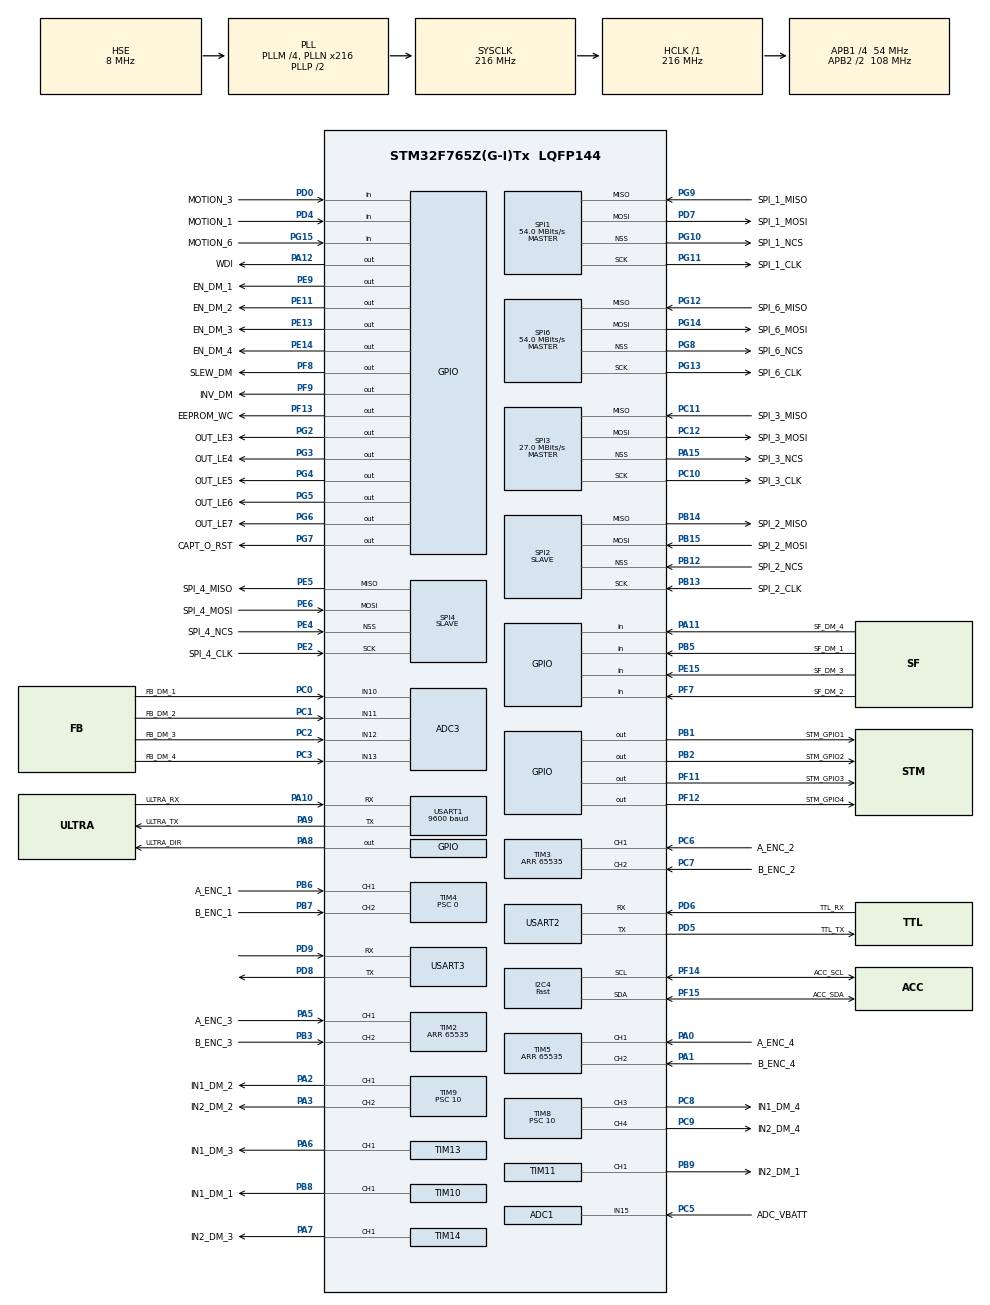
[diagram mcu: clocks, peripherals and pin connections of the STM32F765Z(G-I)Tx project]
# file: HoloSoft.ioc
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SPI6.Mode=SPI_MODE_MASTER
PD7.Mode=Full_Duplex_Master
SPI3.Direction=SPI_DIRECTION_2LINES
SPI4.VirtualType=VM_SLAVE
SPI3.VirtualType=VM_MASTER
SPI1.VirtualType=VM_MASTER
SPI2.VirtualType=VM_SLAVE
VP_ADC1_TempSens_Input.Mode=IN-TempSens
NVIC.TIM6_DAC_IRQn=true\:1\:0\:true\:false\:true\:true\:true
PG4.Signal=GPIO_Output
PG8.Signal=SPI6_NSS
PC12.Signal=SPI3_MOSI
PB14.GPIO_Label=SPI_2_MISO
PG6.GPIO_Label=OUT_LE7
PA14.GPIO_Label=STM_SWCLK
PC6.GPIO_Label=A_ENC_2
PA6.GPIO_Label=IN1_DM_3
PB6.GPIO_Label=A_ENC_1
TIM8.Channel-PWM\ Generation4\ CH4=TIM_CHANNEL_4
PB13.Signal=SPI2_SCK
PD6.GPIO_Label=TTL_RX
PG13.Signal=SPI6_SCK
PE6.GPIO_Label=SPI_4_MOSI
RCC.SYSCLKSource=RCC_SYSCLKSOURCE_PLLCLK
USART3.VirtualMode-Asynchronous=VM_ASYNC
NVIC.SPI4_IRQn=true\:7\:0\:true\:false\:true\:true\:true
PG15.GPIO_Label=MOTION_6
PF7.Signal=GPIO_Input
SH.S_TIM14_CH1.0=TIM14_CH1,PWM Generation1 CH1
I2C4.Timing=0x6000030D
SPI1.Direction=SPI_DIRECTION_2LINES
SPI3.VirtualNSS=VM_NSSHARD
PE2.Mode=Full_Duplex_Slave
PD4.Signal=GPIO_Input
RCC.APB2TimFreq_Value=216000000
PB6.Signal=S_TIM4_CH1
VP_TIM10_VS_ClockSourceINT.Mode=Enable_Timer
PC7.Signal=S_TIM3_CH2
PH1/OSC_OUT.Signal=RCC_OSC_OUT
SPI1.CalculateBaudRate=54.0 MBits/s
PC3.Signal=ADCx_IN13
PD0.Signal=GPIO_Input
PD8.Signal=USART3_TX
PE5.Signal=SPI4_MISO
PB2.Signal=GPIO_Output
ADC3.SamplingTime-2\#ChannelRegularConversion=ADC_SAMPLETIME_3CYCLES
TIM10.Channel=TIM_CHANNEL_1
SH.ADCx_IN15.0=ADC1_IN15,IN15
PB12.GPIO_Label=SPI_2_NCS
PG14.Mode=Full_Duplex_Master
PF12.GPIO_Label=STM_GPIO4
PE9.Signal=GPIO_Output
PB14.Mode=Full_Duplex_Slave
PB1.GPIO_Label=STM_GPIO1
SPI1.DataSize=SPI_DATASIZE_8BIT
PG4.GPIO_Label=OUT_LE5
PE4.GPIO_Label=SPI_4_NCS
SH.S_TIM4_CH2.0=TIM4_CH2,Encoder_Interface
PE2.Signal=SPI4_SCK
PA8.Signal=GPIO_Output
SPI1.VirtualNSS=VM_NSSHARD
TIM4.Period=65535
ADC3.Channel-2\#ChannelRegularConversion=ADC_CHANNEL_12
ADC1.SamplingTime-0\#ChannelRegularConversion=ADC_SAMPLETIME_3CYCLES
TIM9.Prescaler=10
Mcu.Package=LQFP144
PB9.Signal=S_TIM11_CH1
PB1.Signal=GPIO_Output
PB14.GPIO_PuPd=GPIO_PULLUP
TIM8.Channel-PWM\ Generation3\ CH3=TIM_CHANNEL_3
SH.S_TIM8_CH4.0=TIM8_CH4,PWM Generation4 CH4
SPI2.Mode=SPI_MODE_SLAVE
SPI3.Mode=SPI_MODE_MASTER
ADC3.Rank-0\#ChannelRegularConversion=1
PA10.Signal=USART1_RX
PC11.Mode=Full_Duplex_Master
RCC.APB2CLKDivider=RCC_HCLK_DIV2
SH.S_TIM4_CH1.0=TIM4_CH1,Encoder_Interface
PF14.Signal=I2C4_SCL
RCC.APB1TimFreq_Value=108000000
PB13.Mode=Full_Duplex_Slave
VP_TIM14_VS_ClockSourceINT.Mode=Enable_Timer
NVIC.USART1_IRQn=true\:7\:0\:true\:false\:true\:true\:true
TIM9.Period=999
PG12.Signal=SPI6_MISO
TIM9.Channel-PWM\ Generation2\ CH2=TIM_CHANNEL_2
SH.S_TIM8_CH3.0=TIM8_CH3,PWM Generation3 CH3
TIM9.Channel-PWM\ Generation1\ CH1=TIM_CHANNEL_1
I2C4.I2C_Speed_Mode=I2C_Fast
ADC1.Rank-0\#ChannelRegularConversion=1
PG5.Signal=GPIO_Output
PG9.Signal=SPI1_MISO
PA9.GPIO_Label=ULTRA_TX
PG9.Mode=Full_Duplex_Master
PC6.Signal=S_TIM3_CH1
PC2.Signal=ADCx_IN12
PD7.Signal=SPI1_MOSI
PA11.GPIO_Label=SF_DM_4
PF14.GPIO_Label=ACC_SCL
SPI1.CLKPhase=SPI_PHASE_2EDGE
TIM11.Prescaler=10
PC0.Signal=ADCx_IN10
RCC.APB1CLKDivider=RCC_HCLK_DIV4
PD6.Mode=Asynchronous
PF13.GPIO_Label=EEPROM_WC
PG13.GPIO_Label=SPI_6_CLK
PG10.Signal=SPI1_NSS
PF8.GPIO_Label=SLEW_DM
PB8.GPIO_Label=IN1_DM_1
PA8.GPIO_Label=ULTRA_DIR
SPI6.CalculateBaudRate=54.0 MBits/s
TIM13.Channel=TIM_CHANNEL_1
SH.S_TIM9_CH2.0=TIM9_CH2,PWM Generation2 CH2
PA9.Signal=USART1_TX
VP_TIM8_VS_ClockSourceINT.Mode=Internal
SPI4.VirtualNSS=VM_NSSHARD
ADC3.NbrOfConversion=4
PE9.GPIO_Label=EN_DM_1
PD8.Mode=Asynchronous
PB14.Signal=SPI2_MISO
PE2.GPIO_PuPd=GPIO_NOPULL
PA5.Signal=S_TIM2_CH1_ETR
PC12.Mode=Full_Duplex_Master
TIM13.Period=999
PB13.GPIO_PuPd=GPIO_PULLUP
NVIC.SPI1_IRQn=true\:7\:0\:true\:false\:true\:true\:true
VP_TIM13_VS_ClockSourceINT.Mode=Enable_Timer
PE14.Signal=GPIO_Output
PE6.Mode=Full_Duplex_Slave
PE15.Signal=GPIO_Input
TIM14.Channel=TIM_CHANNEL_1
PB15.GPIO_Label=SPI_2_MOSI
TIM13.Prescaler=5
SPI1.Mode=SPI_MODE_MASTER
PG7.GPIO_Label=CAPT_O_RST
PA1.GPIO_Label=B_ENC_4
SH.S_TIM9_CH1.0=TIM9_CH1,PWM Generation1 CH1
PA0/WKUP.GPIO_Label=A_ENC_4
PF13.Signal=GPIO_Output
TIM2.Period=65535
PA13.Mode=Serial_Wire
PG14.GPIO_Label=SPI_6_MOSI
ADC3.Channel-1\#ChannelRegularConversion=ADC_CHANNEL_11
TIM14.Prescaler=5
PE4.GPIO_PuPd=GPIO_NOPULL
TIM8.Period=999
PC7.GPIO_Label=B_ENC_2
ADC3.Rank-1\#ChannelRegularConversion=2
ADC1.SamplingTime-1\#ChannelRegularConversion=ADC_SAMPLETIME_3CYCLES
PB5.Signal=GPIO_Input
ADC1.master=1
PE13.GPIO_Label=EN_DM_3
PA5.GPIO_Label=A_ENC_3
PE5.GPIO_Label=SPI_4_MISO
PC12.GPIO_Label=SPI_3_MOSI
ADC1.Rank-1\#ChannelRegularConversion=2
PG11.Mode=Full_Duplex_Master
PA11.Signal=GPIO_Input
SH.S_TIM2_CH1_ETR.0=TIM2_CH1,Encoder_Interface
ProjectManager.HeapSize=0x200
PF9.Signal=GPIO_Output
SPI4.CLKPhase=SPI_PHASE_2EDGE
NVIC.PriorityGroup=NVIC_PRIORITYGROUP_4
PC3.GPIO_Label=FB_DM_4
SPI2.DataSize=SPI_DATASIZE_8BIT
PG3.GPIO_Label=OUT_LE4
PC1.Signal=ADCx_IN11
PG10.GPIO_Label=SPI_1_NCS
SPI6.VirtualType=VM_MASTER
Mcu.Family=STM32F7
NVIC.USART3_IRQn=true\:0\:0\:false\:false\:true\:true\:true
PG8.Mode=NSS_Signal_Hard_Output
NVIC.SPI6_IRQn=true\:7\:0\:true\:false\:true\:true\:true
SPI2.VirtualNSS=VM_NSSHARD
RCC.CortexFreq_Value=216000000
PG6.Signal=GPIO_Output
ADC3.Channel-3\#ChannelRegularConversion=ADC_CHANNEL_13
PG2.Signal=GPIO_Output
PE11.GPIO_Label=EN_DM_2
USART1.BaudRate=9600
PC10.Signal=SPI3_SCK
TIM4.EncoderMode=TIM_ENCODERMODE_TI12
TIM5.EncoderMode=TIM_ENCODERMODE_TI12
SPI4.Direction=SPI_DIRECTION_2LINES
TIM3.EncoderMode=TIM_ENCODERMODE_TI12
SH.S_TIM5_CH2.0=TIM5_CH2,Encoder_Interface
PC0.GPIO_Label=FB_DM_1
PD0.GPIO_Label=MOTION_3
PA0/WKUP.Signal=S_TIM5_CH1
TIM2.EncoderMode=TIM_ENCODERMODE_TI12
PB13.GPIO_Label=SPI_2_CLK
PG5.GPIO_Label=OUT_LE6
PB15.Signal=SPI2_MOSI
ADC3.Channel-0\#ChannelRegularConversion=ADC_CHANNEL_10
PD9.Mode=Asynchronous
SH.S_TIM13_CH1.0=TIM13_CH1,PWM Generation1 CH1
PG11.Signal=SPI1_SCK
PG15.Signal=GPIO_Input
ADC3.Rank-2\#ChannelRegularConversion=3
ProjectManager.StackSize=0x400
VP_TIM7_VS_ClockSourceINT.Mode=Enable_Timer
NVIC.ADC_IRQn=true\:4\:0\:true\:false\:true\:true\:true
PA15.GPIO_Label=SPI_3_NCS
PA12.Signal=GPIO_Output
SPI1.CLKPolarity=SPI_POLARITY_HIGH
SPI2.CLKPolarity=SPI_POLARITY_HIGH
SPI4.Mode=SPI_MODE_SLAVE
SPI3.CLKPolarity=SPI_POLARITY_HIGH
PH0/OSC_IN.Mode=HSE-External-Oscillator
RCC.HCLKFreq_Value=216000000
TIM3.Period=65535
PF11.GPIO_Label=STM_GPIO3
PF12.Signal=GPIO_Output
SPI6.CLKPolarity=SPI_POLARITY_HIGH
TIM7.Period=199
SPI4.CLKPolarity=SPI_POLARITY_HIGH
RCC.AHBFreq_Value=216000000
SPI3.DataSize=SPI_DATASIZE_8BIT
PD5.Mode=Asynchronous
ADC3.SamplingTime-1\#ChannelRegularConversion=ADC_SAMPLETIME_3CYCLES
ADC1.Channel-0\#ChannelRegularConversion=ADC_CHANNEL_15
RCC.HSE_VALUE=8000000
USART2.VirtualMode-Asynchronous=VM_ASYNC
TIM14.Period=999
PA15.Mode=NSS_Signal_Hard_Output
PE13.Signal=GPIO_Output
PF7.GPIO_Label=SF_DM_2
PA14.Mode=Serial_Wire
PF11.Signal=GPIO_Output
PC11.GPIO_Label=SPI_3_MISO
PA10.GPIO_Label=ULTRA_RX
PB7.Signal=S_TIM4_CH2
NVIC.SPI2_IRQn=true\:7\:0\:true\:false\:true\:true\:true
PG13.Mode=Full_Duplex_Master
PE4.Mode=NSS_Signal_Hard_Input
SH.S_TIM3_CH1.0=TIM3_CH1,Encoder_Interface
TIM6.Period=9999
PH1/OSC_OUT.Mode=HSE-External-Oscillator
PE4.Signal=SPI4_NSS
PF15.Mode=I2C
PD7.GPIO_Label=SPI_1_MOSI
PB7.GPIO_Label=B_ENC_1
PA6.Signal=S_TIM13_CH1
PB12.Mode=NSS_Signal_Hard_Input
PB15.GPIO_PuPd=GPIO_PULLUP
SH.S_TIM10_CH1.0=TIM10_CH1,PWM Generation1 CH1
PD5.GPIO_Label=TTL_TX
PA2.GPIO_Label=IN1_DM_2
PA15.Signal=SPI3_NSS
PF8.Signal=GPIO_Output
NVIC.SPI3_IRQn=true\:7\:0\:true\:false\:true\:true\:true
SPI2.CLKPhase=SPI_PHASE_2EDGE
TIM8.Prescaler=10
PB5.GPIO_Label=SF_DM_1
SH.S_TIM5_CH1.0=TIM5_CH1,Encoder_Interface
PG11.GPIO_Label=SPI_1_CLK
SPI2.Direction=SPI_DIRECTION_2LINES
PC5.Signal=ADCx_IN15
PD6.Signal=USART2_RX
SH.S_TIM11_CH1.0=TIM11_CH1,PWM Generation1 CH1
PE2.GPIO_Label=SPI_4_CLK
PC2.GPIO_Label=FB_DM_3
NVIC.TIM7_IRQn=true\:1\:0\:true\:false\:true\:true\:true
PG2.GPIO_Label=OUT_LE3
PA3.Signal=S_TIM9_CH2
PB3.GPIO_Label=B_ENC_3
RCC.PLLSourceVirtual=RCC_PLLSOURCE_HSE
TIM10.Prescaler=10
SPI6.CLKPhase=SPI_PHASE_2EDGE
ADC3.SamplingTime-3\#ChannelRegularConversion=ADC_SAMPLETIME_3CYCLES
SH.ADCx_IN13.0=ADC3_IN13,IN13
PG7.Signal=GPIO_Output
PB9.GPIO_Label=IN2_DM_1
PA10.Mode=Asynchronous
PC10.GPIO_Label=SPI_3_CLK
PC9.GPIO_Label=IN2_DM_4
SPI4.DataSize=SPI_DATASIZE_8BIT
PG3.Signal=GPIO_Output
PC11.Signal=SPI3_MISO
PC8.Signal=S_TIM8_CH3
TIM6.Prescaler=10800
PC10.Mode=Full_Duplex_Master
PG10.Mode=NSS_Signal_Hard_Output
VP_TIM6_VS_ClockSourceINT.Mode=Enable_Timer
PE14.GPIO_Label=EN_DM_4
PD9.Signal=USART3_RX
PD5.Signal=USART2_TX
ADC3.Rank-3\#ChannelRegularConversion=4
NVIC.USART2_IRQn=true\:7\:0\:true\:false\:true\:true\:true
PA12.GPIO_Label=WDI
VP_TIM11_VS_ClockSourceINT.Mode=Enable_Timer
SPI6.VirtualNSS=VM_NSSHARD
PG8.GPIO_Label=SPI_6_NCS
PC8.GPIO_Label=IN1_DM_4
USART1.VirtualMode-Asynchronous=VM_ASYNC
PA13.Signal=SYS_JTMS-SWDIO
SH.S_TIM2_CH2.0=TIM2_CH2,Encoder_Interface
PA9.Mode=Asynchronous
SH.ADCx_IN12.0=ADC3_IN12,IN12
ADC3.SamplingTime-0\#ChannelRegularConversion=ADC_SAMPLETIME_3CYCLES
PE15.GPIO_Label=SF_DM_3
SPI6.DataSize=SPI_DATASIZE_8BIT
ProjectManager.TargetToolchain=STM32CubeIDE
ADC1.Channel-1\#ChannelRegularConversion=ADC_CHANNEL_TEMPSENSOR
RCC.USBFreq_Value=216000000
PF9.GPIO_Label=INV_DM
TIM4.Prescaler=0
PE11.Signal=GPIO_Output
RCC.LSE_VALUE=32768
PA1.Signal=S_TIM5_CH2
PG9.GPIO_Label=SPI_1_MISO
SH.S_TIM3_CH2.0=TIM3_CH2,Encoder_Interface
PG14.Signal=SPI6_MOSI
TIM7.Prescaler=10800
board=custom
PG12.Mode=Full_Duplex_Master
SPI3.CLKPhase=SPI_PHASE_2EDGE
RCC.VCOOutputFreq_Value=432000000
PB15.Mode=Full_Duplex_Slave
VP_TIM9_VS_ClockSourceINT.Mode=Internal
TIM11.Period=999
TIM10.Period=999
PH0/OSC_IN.Signal=RCC_OSC_IN
RCC.APB2Freq_Value=108000000
SPI3.CalculateBaudRate=27.0 MBits/s
SH.ADCx_IN11.0=ADC3_IN11,IN11
PD4.GPIO_Label=MOTION_1
PF14.Mode=I2C
PE5.Mode=Full_Duplex_Slave
PC1.GPIO_Label=FB_DM_2
PF15.GPIO_Label=ACC_SDA
SPI6.Direction=SPI_DIRECTION_2LINES
PF15.Signal=I2C4_SDA
PE6.Signal=SPI4_MOSI
ADC1.NbrOfConversion=2
Mcu.Name=STM32F765Z(G-I)Tx
PA2.Signal=S_TIM9_CH1
PA13.GPIO_Label=STM_SWSDIO
PB3.Signal=S_TIM2_CH2
RCC.SYSCLKFreq_VALUE=216000000
PA7.GPIO_Label=IN2_DM_3
PC5.GPIO_Label=ADC_VBATT
PA14.Signal=SYS_JTCK-SWCLK
SH.ADCx_IN10.0=ADC3_IN10,IN10
PB2.GPIO_Label=STM_GPIO2
PG12.GPIO_Label=SPI_6_MISO
RCC.HSI_VALUE=16000000
ADC1.NbrOfConversionFlag=1
RCC.PLLM=4
RCC.PLLN=216
TIM11.Channel=TIM_CHANNEL_1
PB8.Signal=S_TIM10_CH1
TIM5.Period=65535
PC9.Signal=S_TIM8_CH4
RCC.APB1Freq_Value=54000000
ADC3.NbrOfConversionFlag=1
PB12.Signal=SPI2_NSS
PA3.GPIO_Label=IN2_DM_2
PA7.Signal=S_TIM14_CH1

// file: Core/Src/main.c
/* USER CODE BEGIN Header */
/**
  ******************************************************************************
  * @file           : main.c
  * @brief          : Main program body
  ******************************************************************************
  * @attention
  *
  * <h2><center>&copy; Copyright (c) 2019 STMicroelectronics.
  * All rights reserved.</center></h2>
  *
  * This software component is licensed by ST under BSD 3-Clause license,
  * the "License"; You may not use this file except in compliance with the
  * License. You may obtain a copy of the License at:
  *                        opensource.org/licenses/BSD-3-Clause
  *
  ******************************************************************************
  */
/* USER CODE END Header */

#include "main.h"

/* USER CODE BEGIN Includes */
#include <stdio.h>
#include <string.h>
#include <math.h>
/* Includes ------------------------------------------------------------------*/
#include "main.h"
#include "secretary.h"
#include "brain.h"
#include "it.h"
#include "odometry.h"
/* Private includes ----------------------------------------------------------*/
/* USER CODE END Includes */

/* USER CODE BEGIN PD */
#define MATHS_PI				3.14159
//#define MATHS_PI_x2				6.28318
//#define CONVERT_RAD_TO_RPM	(60 / (MATHS_PI_x2))	// Coefficient de convertion RAD vers RPM

/* USER CODE END PD */

ADC_HandleTypeDef hadc1;
ADC_HandleTypeDef hadc3;

I2C_HandleTypeDef hi2c4;

SPI_HandleTypeDef hspi1;
SPI_HandleTypeDef hspi2;
SPI_HandleTypeDef hspi3;
SPI_HandleTypeDef hspi4;
SPI_HandleTypeDef hspi6;

TIM_HandleTypeDef htim2;
TIM_HandleTypeDef htim3;
TIM_HandleTypeDef htim4;
TIM_HandleTypeDef htim5;
TIM_HandleTypeDef htim6;
TIM_HandleTypeDef htim7;
TIM_HandleTypeDef htim8;
TIM_HandleTypeDef htim9;
TIM_HandleTypeDef htim10;
TIM_HandleTypeDef htim11;
TIM_HandleTypeDef htim13;
TIM_HandleTypeDef htim14;

UART_HandleTypeDef huart1;
UART_HandleTypeDef huart2;
UART_HandleTypeDef huart3;

void SystemClock_Config(void);
static void MX_GPIO_Init(void);
static void MX_SPI2_Init(void);
static void MX_USART1_UART_Init(void);
static void MX_I2C4_Init(void);
static void MX_SPI1_Init(void);
static void MX_SPI3_Init(void);
static void MX_SPI6_Init(void);
static void MX_USART2_UART_Init(void);
static void MX_USART3_UART_Init(void);
static void MX_SPI4_Init(void);
static void MX_ADC1_Init(void);
static void MX_ADC3_Init(void);
static void MX_TIM2_Init(void);
static void MX_TIM3_Init(void);
static void MX_TIM4_Init(void);
static void MX_TIM5_Init(void);
static void MX_TIM14_Init(void);
static void MX_TIM8_Init(void);
static void MX_TIM9_Init(void);
static void MX_TIM10_Init(void);
static void MX_TIM11_Init(void);
static void MX_TIM13_Init(void);
static void MX_TIM7_Init(void);
static void MX_TIM6_Init(void);
/* USER CODE BEGIN PFP */
static void board_message_init(void);
static void board_motors_init(void);
static void board_encodeurs_init(void);

/* USER CODE END PFP */

/* USER CODE BEGIN 0 */

uint16_t j=0;
uint8_t test_freq = 0;

/* USER CODE END 0 */

int main(void)
{

  /* MCU Configuration--------------------------------------------------------*/

  /* Reset of all peripherals, Initializes the Flash interface and the Systick. */
  HAL_Init();

  /* Configure the system clock */
  SystemClock_Config();

  /* Initialize all configured peripherals */
  MX_GPIO_Init();
  MX_SPI2_Init();
  MX_USART1_UART_Init();
  MX_I2C4_Init();
  MX_SPI1_Init();
  MX_SPI3_Init();
  MX_SPI6_Init();
  MX_USART2_UART_Init();
  MX_USART3_UART_Init();
  MX_SPI4_Init();
  MX_ADC1_Init();
  MX_ADC3_Init();
  MX_TIM2_Init();
  MX_TIM3_Init();
  MX_TIM4_Init();
  MX_TIM5_Init();
  MX_TIM14_Init();
  MX_TIM8_Init();
  MX_TIM9_Init();
  MX_TIM10_Init();
  MX_TIM11_Init();
  MX_TIM13_Init();
  MX_TIM7_Init();
  MX_TIM6_Init();
  /* USER CODE BEGIN 2 */

  board_message_init();
  board_motors_init();
  board_encodeurs_init();
  ODOMETRY_init();
  IT_init();
  BRAIN_main();
  /* USER CODE END 2 */

  /* Infinite loop */
  while (1)
  {

  }
}

void SystemClock_Config(void)
{
  RCC_OscInitTypeDef RCC_OscInitStruct = {0};
  RCC_ClkInitTypeDef RCC_ClkInitStruct = {0};
  RCC_PeriphCLKInitTypeDef PeriphClkInitStruct = {0};

  /** Configure the main internal regulator output voltage
  */
  __HAL_RCC_PWR_CLK_ENABLE();
  __HAL_PWR_VOLTAGESCALING_CONFIG(PWR_REGULATOR_VOLTAGE_SCALE1);
  /** Initializes the CPU, AHB and APB busses clocks
  */
  RCC_OscInitStruct.OscillatorType = RCC_OSCILLATORTYPE_HSE;
  RCC_OscInitStruct.HSEState = RCC_HSE_ON;
  RCC_OscInitStruct.PLL.PLLState = RCC_PLL_ON;
  RCC_OscInitStruct.PLL.PLLSource = RCC_PLLSOURCE_HSE;
  RCC_OscInitStruct.PLL.PLLM = 4;
  RCC_OscInitStruct.PLL.PLLN = 216;
  RCC_OscInitStruct.PLL.PLLP = RCC_PLLP_DIV2;
  RCC_OscInitStruct.PLL.PLLQ = 2;
  if (HAL_RCC_OscConfig(&RCC_OscInitStruct) != HAL_OK)
  {
    Error_Handler();
  }
  /** Activate the Over-Drive mode
  */
  if (HAL_PWREx_EnableOverDrive() != HAL_OK)
  {
    Error_Handler();
  }
  /** Initializes the CPU, AHB and APB busses clocks
  */
  RCC_ClkInitStruct.ClockType = RCC_CLOCKTYPE_HCLK|RCC_CLOCKTYPE_SYSCLK
                              |RCC_CLOCKTYPE_PCLK1|RCC_CLOCKTYPE_PCLK2;
  RCC_ClkInitStruct.SYSCLKSource = RCC_SYSCLKSOURCE_PLLCLK;
  RCC_ClkInitStruct.AHBCLKDivider = RCC_SYSCLK_DIV1;
  RCC_ClkInitStruct.APB1CLKDivider = RCC_HCLK_DIV4;
  RCC_ClkInitStruct.APB2CLKDivider = RCC_HCLK_DIV2;

  if (HAL_RCC_ClockConfig(&RCC_ClkInitStruct, FLASH_LATENCY_7) != HAL_OK)
  {
    Error_Handler();
  }
  PeriphClkInitStruct.PeriphClockSelection = RCC_PERIPHCLK_USART1|RCC_PERIPHCLK_USART2
                              |RCC_PERIPHCLK_USART3|RCC_PERIPHCLK_I2C4;
  PeriphClkInitStruct.Usart1ClockSelection = RCC_USART1CLKSOURCE_PCLK2;
  PeriphClkInitStruct.Usart2ClockSelection = RCC_USART2CLKSOURCE_PCLK1;
  PeriphClkInitStruct.Usart3ClockSelection = RCC_USART3CLKSOURCE_PCLK1;
  PeriphClkInitStruct.I2c4ClockSelection = RCC_I2C4CLKSOURCE_PCLK1;
  if (HAL_RCCEx_PeriphCLKConfig(&PeriphClkInitStruct) != HAL_OK)
  {
    Error_Handler();
  }
}

static void MX_ADC1_Init(void)
{

  ADC_ChannelConfTypeDef sConfig = {0};

  /** Configure the global features of the ADC (Clock, Resolution, Data Alignment and number of conversion)
  */
  hadc1.Instance = ADC1;
  hadc1.Init.ClockPrescaler = ADC_CLOCK_SYNC_PCLK_DIV4;
  hadc1.Init.Resolution = ADC_RESOLUTION_12B;
  hadc1.Init.ScanConvMode = ADC_SCAN_ENABLE;
  hadc1.Init.ContinuousConvMode = DISABLE;
  hadc1.Init.DiscontinuousConvMode = DISABLE;
  hadc1.Init.ExternalTrigConvEdge = ADC_EXTERNALTRIGCONVEDGE_NONE;
  hadc1.Init.ExternalTrigConv = ADC_SOFTWARE_START;
  hadc1.Init.DataAlign = ADC_DATAALIGN_RIGHT;
  hadc1.Init.NbrOfConversion = 2;
  hadc1.Init.DMAContinuousRequests = DISABLE;
  hadc1.Init.EOCSelection = ADC_EOC_SINGLE_CONV;
  if (HAL_ADC_Init(&hadc1) != HAL_OK)
  {
    Error_Handler();
  }
  /** Configure for the selected ADC regular channel its corresponding rank in the sequencer and its sample time.
  */
  sConfig.Channel = ADC_CHANNEL_15;
  sConfig.Rank = ADC_REGULAR_RANK_1;
  sConfig.SamplingTime = ADC_SAMPLETIME_3CYCLES;
  if (HAL_ADC_ConfigChannel(&hadc1, &sConfig) != HAL_OK)
  {
    Error_Handler();
  }
  /** Configure for the selected ADC regular channel its corresponding rank in the sequencer and its sample time.
  */
  sConfig.Channel = ADC_CHANNEL_TEMPSENSOR;
  sConfig.Rank = ADC_REGULAR_RANK_2;
  if (HAL_ADC_ConfigChannel(&hadc1, &sConfig) != HAL_OK)
  {
    Error_Handler();
  }

}

static void MX_ADC3_Init(void)
{

  ADC_ChannelConfTypeDef sConfig = {0};

  /** Configure the global features of the ADC (Clock, Resolution, Data Alignment and number of conversion)
  */
  hadc3.Instance = ADC3;
  hadc3.Init.ClockPrescaler = ADC_CLOCK_SYNC_PCLK_DIV4;
  hadc3.Init.Resolution = ADC_RESOLUTION_12B;
  hadc3.Init.ScanConvMode = ADC_SCAN_ENABLE;
  hadc3.Init.ContinuousConvMode = DISABLE;
  hadc3.Init.DiscontinuousConvMode = DISABLE;
  hadc3.Init.ExternalTrigConvEdge = ADC_EXTERNALTRIGCONVEDGE_NONE;
  hadc3.Init.ExternalTrigConv = ADC_SOFTWARE_START;
  hadc3.Init.DataAlign = ADC_DATAALIGN_RIGHT;
  hadc3.Init.NbrOfConversion = 4;
  hadc3.Init.DMAContinuousRequests = DISABLE;
  hadc3.Init.EOCSelection = ADC_EOC_SINGLE_CONV;
  if (HAL_ADC_Init(&hadc3) != HAL_OK)
  {
    Error_Handler();
  }
  /** Configure for the selected ADC regular channel its corresponding rank in the sequencer and its sample time.
  */
  sConfig.Channel = ADC_CHANNEL_10;
  sConfig.Rank = ADC_REGULAR_RANK_1;
  sConfig.SamplingTime = ADC_SAMPLETIME_3CYCLES;
  if (HAL_ADC_ConfigChannel(&hadc3, &sConfig) != HAL_OK)
  {
    Error_Handler();
  }
  /** Configure for the selected ADC regular channel its corresponding rank in the sequencer and its sample time.
  */
  sConfig.Channel = ADC_CHANNEL_11;
  sConfig.Rank = ADC_REGULAR_RANK_2;
  if (HAL_ADC_ConfigChannel(&hadc3, &sConfig) != HAL_OK)
  {
    Error_Handler();
  }
  /** Configure for the selected ADC regular channel its corresponding rank in the sequencer and its sample time.
  */
  sConfig.Channel = ADC_CHANNEL_12;
  sConfig.Rank = ADC_REGULAR_RANK_3;
  if (HAL_ADC_ConfigChannel(&hadc3, &sConfig) != HAL_OK)
  {
    Error_Handler();
  }
  /** Configure for the selected ADC regular channel its corresponding rank in the sequencer and its sample time.
  */
  sConfig.Channel = ADC_CHANNEL_13;
  sConfig.Rank = ADC_REGULAR_RANK_4;
  if (HAL_ADC_ConfigChannel(&hadc3, &sConfig) != HAL_OK)
  {
    Error_Handler();
  }

}

static void MX_I2C4_Init(void)
{

  hi2c4.Instance = I2C4;
  hi2c4.Init.Timing = 0x6000030D;
  hi2c4.Init.OwnAddress1 = 0;
  hi2c4.Init.AddressingMode = I2C_ADDRESSINGMODE_7BIT;
  hi2c4.Init.DualAddressMode = I2C_DUALADDRESS_DISABLE;
  hi2c4.Init.OwnAddress2 = 0;
  hi2c4.Init.OwnAddress2Masks = I2C_OA2_NOMASK;
  hi2c4.Init.GeneralCallMode = I2C_GENERALCALL_DISABLE;
  hi2c4.Init.NoStretchMode = I2C_NOSTRETCH_DISABLE;
  if (HAL_I2C_Init(&hi2c4) != HAL_OK)
  {
    Error_Handler();
  }
  /** Configure Analogue filter
  */
  if (HAL_I2CEx_ConfigAnalogFilter(&hi2c4, I2C_ANALOGFILTER_ENABLE) != HAL_OK)
  {
    Error_Handler();
  }
  /** Configure Digital filter
  */
  if (HAL_I2CEx_ConfigDigitalFilter(&hi2c4, 0) != HAL_OK)
  {
    Error_Handler();
  }

}

static void MX_SPI1_Init(void)
{

  /* SPI1 parameter configuration*/
  hspi1.Instance = SPI1;
  hspi1.Init.Mode = SPI_MODE_MASTER;
  hspi1.Init.Direction = SPI_DIRECTION_2LINES;
  hspi1.Init.DataSize = SPI_DATASIZE_8BIT;
  hspi1.Init.CLKPolarity = SPI_POLARITY_HIGH;
  hspi1.Init.CLKPhase = SPI_PHASE_2EDGE;
  hspi1.Init.NSS = SPI_NSS_HARD_OUTPUT;
  hspi1.Init.BaudRatePrescaler = SPI_BAUDRATEPRESCALER_2;
  hspi1.Init.FirstBit = SPI_FIRSTBIT_MSB;
  hspi1.Init.TIMode = SPI_TIMODE_DISABLE;
  hspi1.Init.CRCCalculation = SPI_CRCCALCULATION_DISABLE;
  hspi1.Init.CRCPolynomial = 7;
  hspi1.Init.CRCLength = SPI_CRC_LENGTH_DATASIZE;
  hspi1.Init.NSSPMode = SPI_NSS_PULSE_DISABLE;
  if (HAL_SPI_Init(&hspi1) != HAL_OK)
  {
    Error_Handler();
  }

}

static void MX_SPI2_Init(void)
{

  /* SPI2 parameter configuration*/
  hspi2.Instance = SPI2;
  hspi2.Init.Mode = SPI_MODE_SLAVE;
  hspi2.Init.Direction = SPI_DIRECTION_2LINES;
  hspi2.Init.DataSize = SPI_DATASIZE_8BIT;
  hspi2.Init.CLKPolarity = SPI_POLARITY_HIGH;
  hspi2.Init.CLKPhase = SPI_PHASE_2EDGE;
  hspi2.Init.NSS = SPI_NSS_HARD_INPUT;
  hspi2.Init.FirstBit = SPI_FIRSTBIT_MSB;
  hspi2.Init.TIMode = SPI_TIMODE_DISABLE;
  hspi2.Init.CRCCalculation = SPI_CRCCALCULATION_DISABLE;
  hspi2.Init.CRCPolynomial = 7;
  hspi2.Init.CRCLength = SPI_CRC_LENGTH_DATASIZE;
  hspi2.Init.NSSPMode = SPI_NSS_PULSE_DISABLE;
  if (HAL_SPI_Init(&hspi2) != HAL_OK)
  {
    Error_Handler();
  }

}

static void MX_SPI3_Init(void)
{

  /* SPI3 parameter configuration*/
  hspi3.Instance = SPI3;
  hspi3.Init.Mode = SPI_MODE_MASTER;
  hspi3.Init.Direction = SPI_DIRECTION_2LINES;
  hspi3.Init.DataSize = SPI_DATASIZE_8BIT;
  hspi3.Init.CLKPolarity = SPI_POLARITY_HIGH;
  hspi3.Init.CLKPhase = SPI_PHASE_2EDGE;
  hspi3.Init.NSS = SPI_NSS_HARD_OUTPUT;
  hspi3.Init.BaudRatePrescaler = SPI_BAUDRATEPRESCALER_2;
  hspi3.Init.FirstBit = SPI_FIRSTBIT_MSB;
  hspi3.Init.TIMode = SPI_TIMODE_DISABLE;
  hspi3.Init.CRCCalculation = SPI_CRCCALCULATION_DISABLE;
  hspi3.Init.CRCPolynomial = 7;
  hspi3.Init.CRCLength = SPI_CRC_LENGTH_DATASIZE;
  hspi3.Init.NSSPMode = SPI_NSS_PULSE_DISABLE;
  if (HAL_SPI_Init(&hspi3) != HAL_OK)
  {
    Error_Handler();
  }

}

static void MX_SPI4_Init(void)
{

  /* SPI4 parameter configuration*/
  hspi4.Instance = SPI4;
  hspi4.Init.Mode = SPI_MODE_SLAVE;
  hspi4.Init.Direction = SPI_DIRECTION_2LINES;
  hspi4.Init.DataSize = SPI_DATASIZE_8BIT;
  hspi4.Init.CLKPolarity = SPI_POLARITY_HIGH;
  hspi4.Init.CLKPhase = SPI_PHASE_2EDGE;
  hspi4.Init.NSS = SPI_NSS_HARD_INPUT;
  hspi4.Init.FirstBit = SPI_FIRSTBIT_MSB;
  hspi4.Init.TIMode = SPI_TIMODE_DISABLE;
  hspi4.Init.CRCCalculation = SPI_CRCCALCULATION_DISABLE;
  hspi4.Init.CRCPolynomial = 7;
  hspi4.Init.CRCLength = SPI_CRC_LENGTH_DATASIZE;
  hspi4.Init.NSSPMode = SPI_NSS_PULSE_DISABLE;
  if (HAL_SPI_Init(&hspi4) != HAL_OK)
  {
    Error_Handler();
  }

}

static void MX_SPI6_Init(void)
{

  /* SPI6 parameter configuration*/
  hspi6.Instance = SPI6;
  hspi6.Init.Mode = SPI_MODE_MASTER;
  hspi6.Init.Direction = SPI_DIRECTION_2LINES;
  hspi6.Init.DataSize = SPI_DATASIZE_8BIT;
  hspi6.Init.CLKPolarity = SPI_POLARITY_HIGH;
  hspi6.Init.CLKPhase = SPI_PHASE_2EDGE;
  hspi6.Init.NSS = SPI_NSS_HARD_OUTPUT;
  hspi6.Init.BaudRatePrescaler = SPI_BAUDRATEPRESCALER_2;
  hspi6.Init.FirstBit = SPI_FIRSTBIT_MSB;
  hspi6.Init.TIMode = SPI_TIMODE_DISABLE;
  hspi6.Init.CRCCalculation = SPI_CRCCALCULATION_DISABLE;
  hspi6.Init.CRCPolynomial = 7;
  hspi6.Init.CRCLength = SPI_CRC_LENGTH_DATASIZE;
  hspi6.Init.NSSPMode = SPI_NSS_PULSE_DISABLE;
  if (HAL_SPI_Init(&hspi6) != HAL_OK)
  {
    Error_Handler();
  }

}

static void MX_TIM2_Init(void)
{

  TIM_Encoder_InitTypeDef sConfig = {0};
  TIM_MasterConfigTypeDef sMasterConfig = {0};

  htim2.Instance = TIM2;
  htim2.Init.Prescaler = 0;
  htim2.Init.CounterMode = TIM_COUNTERMODE_UP;
  htim2.Init.Period = 65535;
  htim2.Init.ClockDivision = TIM_CLOCKDIVISION_DIV1;
  htim2.Init.AutoReloadPreload = TIM_AUTORELOAD_PRELOAD_DISABLE;
  sConfig.EncoderMode = TIM_ENCODERMODE_TI12;
  sConfig.IC1Polarity = TIM_ICPOLARITY_RISING;
  sConfig.IC1Selection = TIM_ICSELECTION_DIRECTTI;
  sConfig.IC1Prescaler = TIM_ICPSC_DIV1;
  sConfig.IC1Filter = 0;
  sConfig.IC2Polarity = TIM_ICPOLARITY_RISING;
  sConfig.IC2Selection = TIM_ICSELECTION_DIRECTTI;
  sConfig.IC2Prescaler = TIM_ICPSC_DIV1;
  sConfig.IC2Filter = 0;
  if (HAL_TIM_Encoder_Init(&htim2, &sConfig) != HAL_OK)
  {
    Error_Handler();
  }
  sMasterConfig.MasterOutputTrigger = TIM_TRGO_RESET;
  sMasterConfig.MasterSlaveMode = TIM_MASTERSLAVEMODE_DISABLE;
  if (HAL_TIMEx_MasterConfigSynchronization(&htim2, &sMasterConfig) != HAL_OK)
  {
    Error_Handler();
  }

}

static void MX_TIM3_Init(void)
{

  TIM_Encoder_InitTypeDef sConfig = {0};
  TIM_MasterConfigTypeDef sMasterConfig = {0};

  htim3.Instance = TIM3;
  htim3.Init.Prescaler = 0;
  htim3.Init.CounterMode = TIM_COUNTERMODE_UP;
  htim3.Init.Period = 65535;
  htim3.Init.ClockDivision = TIM_CLOCKDIVISION_DIV1;
  htim3.Init.AutoReloadPreload = TIM_AUTORELOAD_PRELOAD_DISABLE;
  sConfig.EncoderMode = TIM_ENCODERMODE_TI12;
  sConfig.IC1Polarity = TIM_ICPOLARITY_RISING;
  sConfig.IC1Selection = TIM_ICSELECTION_DIRECTTI;
  sConfig.IC1Prescaler = TIM_ICPSC_DIV1;
  sConfig.IC1Filter = 0;
  sConfig.IC2Polarity = TIM_ICPOLARITY_RISING;
  sConfig.IC2Selection = TIM_ICSELECTION_DIRECTTI;
  sConfig.IC2Prescaler = TIM_ICPSC_DIV1;
  sConfig.IC2Filter = 0;
  if (HAL_TIM_Encoder_Init(&htim3, &sConfig) != HAL_OK)
  {
    Error_Handler();
  }
  sMasterConfig.MasterOutputTrigger = TIM_TRGO_RESET;
  sMasterConfig.MasterSlaveMode = TIM_MASTERSLAVEMODE_DISABLE;
  if (HAL_TIMEx_MasterConfigSynchronization(&htim3, &sMasterConfig) != HAL_OK)
  {
    Error_Handler();
  }

}

static void MX_TIM4_Init(void)
{

  TIM_Encoder_InitTypeDef sConfig = {0};
  TIM_MasterConfigTypeDef sMasterConfig = {0};

  htim4.Instance = TIM4;
  htim4.Init.Prescaler = 0;
  htim4.Init.CounterMode = TIM_COUNTERMODE_UP;
  htim4.Init.Period = 65535;
  htim4.Init.ClockDivision = TIM_CLOCKDIVISION_DIV1;
  htim4.Init.AutoReloadPreload = TIM_AUTORELOAD_PRELOAD_DISABLE;
  sConfig.EncoderMode = TIM_ENCODERMODE_TI12;
  sConfig.IC1Polarity = TIM_ICPOLARITY_RISING;
  sConfig.IC1Selection = TIM_ICSELECTION_DIRECTTI;
  sConfig.IC1Prescaler = TIM_ICPSC_DIV1;
  sConfig.IC1Filter = 0;
  sConfig.IC2Polarity = TIM_ICPOLARITY_RISING;
  sConfig.IC2Selection = TIM_ICSELECTION_DIRECTTI;
  sConfig.IC2Prescaler = TIM_ICPSC_DIV1;
  sConfig.IC2Filter = 0;
  if (HAL_TIM_Encoder_Init(&htim4, &sConfig) != HAL_OK)
  {
    Error_Handler();
  }
  sMasterConfig.MasterOutputTrigger = TIM_TRGO_RESET;
  sMasterConfig.MasterSlaveMode = TIM_MASTERSLAVEMODE_DISABLE;
  if (HAL_TIMEx_MasterConfigSynchronization(&htim4, &sMasterConfig) != HAL_OK)
  {
    Error_Handler();
  }

}

static void MX_TIM5_Init(void)
{

  TIM_Encoder_InitTypeDef sConfig = {0};
  TIM_MasterConfigTypeDef sMasterConfig = {0};

  htim5.Instance = TIM5;
  htim5.Init.Prescaler = 0;
  htim5.Init.CounterMode = TIM_COUNTERMODE_UP;
  htim5.Init.Period = 65535;
  htim5.Init.ClockDivision = TIM_CLOCKDIVISION_DIV1;
  htim5.Init.AutoReloadPreload = TIM_AUTORELOAD_PRELOAD_DISABLE;
  sConfig.EncoderMode = TIM_ENCODERMODE_TI12;
  sConfig.IC1Polarity = TIM_ICPOLARITY_RISING;
  sConfig.IC1Selection = TIM_ICSELECTION_DIRECTTI;
  sConfig.IC1Prescaler = TIM_ICPSC_DIV1;
  sConfig.IC1Filter = 0;
  sConfig.IC2Polarity = TIM_ICPOLARITY_RISING;
  sConfig.IC2Selection = TIM_ICSELECTION_DIRECTTI;
  sConfig.IC2Prescaler = TIM_ICPSC_DIV1;
  sConfig.IC2Filter = 0;
  if (HAL_TIM_Encoder_Init(&htim5, &sConfig) != HAL_OK)
  {
    Error_Handler();
  }
  sMasterConfig.MasterOutputTrigger = TIM_TRGO_RESET;
  sMasterConfig.MasterSlaveMode = TIM_MASTERSLAVEMODE_DISABLE;
  if (HAL_TIMEx_MasterConfigSynchronization(&htim5, &sMasterConfig) != HAL_OK)
  {
    Error_Handler();
  }

}

static void MX_TIM6_Init(void)
{

  TIM_MasterConfigTypeDef sMasterConfig = {0};

  htim6.Instance = TIM6;
  htim6.Init.Prescaler = 10800;
  htim6.Init.CounterMode = TIM_COUNTERMODE_UP;
  htim6.Init.Period = 9999;
  htim6.Init.AutoReloadPreload = TIM_AUTORELOAD_PRELOAD_DISABLE;
  if (HAL_TIM_Base_Init(&htim6) != HAL_OK)
  {
    Error_Handler();
  }
  sMasterConfig.MasterOutputTrigger = TIM_TRGO_RESET;
  sMasterConfig.MasterSlaveMode = TIM_MASTERSLAVEMODE_DISABLE;
  if (HAL_TIMEx_MasterConfigSynchronization(&htim6, &sMasterConfig) != HAL_OK)
  {
    Error_Handler();
  }

}

static void MX_TIM7_Init(void)
{

  TIM_MasterConfigTypeDef sMasterConfig = {0};

  htim7.Instance = TIM7;
  htim7.Init.Prescaler = 10800;
  htim7.Init.CounterMode = TIM_COUNTERMODE_UP;
  htim7.Init.Period = 199;
  htim7.Init.AutoReloadPreload = TIM_AUTORELOAD_PRELOAD_DISABLE;
  if (HAL_TIM_Base_Init(&htim7) != HAL_OK)
  {
    Error_Handler();
  }
  sMasterConfig.MasterOutputTrigger = TIM_TRGO_RESET;
  sMasterConfig.MasterSlaveMode = TIM_MASTERSLAVEMODE_DISABLE;
  if (HAL_TIMEx_MasterConfigSynchronization(&htim7, &sMasterConfig) != HAL_OK)
  {
    Error_Handler();
  }

}

static void MX_TIM8_Init(void)
{

  TIM_ClockConfigTypeDef sClockSourceConfig = {0};
  TIM_MasterConfigTypeDef sMasterConfig = {0};
  TIM_OC_InitTypeDef sConfigOC = {0};
  TIM_BreakDeadTimeConfigTypeDef sBreakDeadTimeConfig = {0};

  htim8.Instance = TIM8;
  htim8.Init.Prescaler = 10;
  htim8.Init.CounterMode = TIM_COUNTERMODE_UP;
  htim8.Init.Period = 999;
  htim8.Init.ClockDivision = TIM_CLOCKDIVISION_DIV1;
  htim8.Init.RepetitionCounter = 0;
  htim8.Init.AutoReloadPreload = TIM_AUTORELOAD_PRELOAD_DISABLE;
  if (HAL_TIM_Base_Init(&htim8) != HAL_OK)
  {
    Error_Handler();
  }
  sClockSourceConfig.ClockSource = TIM_CLOCKSOURCE_INTERNAL;
  if (HAL_TIM_ConfigClockSource(&htim8, &sClockSourceConfig) != HAL_OK)
  {
    Error_Handler();
  }
  if (HAL_TIM_PWM_Init(&htim8) != HAL_OK)
  {
    Error_Handler();
  }
  sMasterConfig.MasterOutputTrigger = TIM_TRGO_RESET;
  sMasterConfig.MasterOutputTrigger2 = TIM_TRGO2_RESET;
  sMasterConfig.MasterSlaveMode = TIM_MASTERSLAVEMODE_DISABLE;
  if (HAL_TIMEx_MasterConfigSynchronization(&htim8, &sMasterConfig) != HAL_OK)
  {
    Error_Handler();
  }
  sConfigOC.OCMode = TIM_OCMODE_PWM1;
  sConfigOC.Pulse = 0;
  sConfigOC.OCPolarity = TIM_OCPOLARITY_HIGH;
  sConfigOC.OCNPolarity = TIM_OCNPOLARITY_HIGH;
  sConfigOC.OCFastMode = TIM_OCFAST_DISABLE;
  sConfigOC.OCIdleState = TIM_OCIDLESTATE_RESET;
  sConfigOC.OCNIdleState = TIM_OCNIDLESTATE_RESET;
  if (HAL_TIM_PWM_ConfigChannel(&htim8, &sConfigOC, TIM_CHANNEL_3) != HAL_OK)
  {
    Error_Handler();
  }
  if (HAL_TIM_PWM_ConfigChannel(&htim8, &sConfigOC, TIM_CHANNEL_4) != HAL_OK)
  {
    Error_Handler();
  }
  sBreakDeadTimeConfig.OffStateRunMode = TIM_OSSR_DISABLE;
  sBreakDeadTimeConfig.OffStateIDLEMode = TIM_OSSI_DISABLE;
  sBreakDeadTimeConfig.LockLevel = TIM_LOCKLEVEL_OFF;
  sBreakDeadTimeConfig.DeadTime = 0;
  sBreakDeadTimeConfig.BreakState = TIM_BREAK_DISABLE;
  sBreakDeadTimeConfig.BreakPolarity = TIM_BREAKPOLARITY_HIGH;
  sBreakDeadTimeConfig.BreakFilter = 0;
  sBreakDeadTimeConfig.Break2State = TIM_BREAK2_DISABLE;
  sBreakDeadTimeConfig.Break2Polarity = TIM_BREAK2POLARITY_HIGH;
  sBreakDeadTimeConfig.Break2Filter = 0;
  sBreakDeadTimeConfig.AutomaticOutput = TIM_AUTOMATICOUTPUT_DISABLE;
  if (HAL_TIMEx_ConfigBreakDeadTime(&htim8, &sBreakDeadTimeConfig) != HAL_OK)
  {
    Error_Handler();
  }
  /* USER CODE BEGIN TIM8_Init 2 */
  HAL_TIM_MspPostInit(&htim8);
  /* USER CODE END TIM8_Init 2 */
  HAL_TIM_MspPostInit(&htim8);

}

static void MX_TIM9_Init(void)
{

  TIM_ClockConfigTypeDef sClockSourceConfig = {0};
  TIM_OC_InitTypeDef sConfigOC = {0};

  htim9.Instance = TIM9;
  htim9.Init.Prescaler = 10;
  htim9.Init.CounterMode = TIM_COUNTERMODE_UP;
  htim9.Init.Period = 999;
  htim9.Init.ClockDivision = TIM_CLOCKDIVISION_DIV1;
  htim9.Init.AutoReloadPreload = TIM_AUTORELOAD_PRELOAD_DISABLE;
  if (HAL_TIM_Base_Init(&htim9) != HAL_OK)
  {
    Error_Handler();
  }
  sClockSourceConfig.ClockSource = TIM_CLOCKSOURCE_INTERNAL;
  if (HAL_TIM_ConfigClockSource(&htim9, &sClockSourceConfig) != HAL_OK)
  {
    Error_Handler();
  }
  if (HAL_TIM_PWM_Init(&htim9) != HAL_OK)
  {
    Error_Handler();
  }
  sConfigOC.OCMode = TIM_OCMODE_PWM1;
  sConfigOC.Pulse = 0;
  sConfigOC.OCPolarity = TIM_OCPOLARITY_HIGH;
  sConfigOC.OCFastMode = TIM_OCFAST_DISABLE;
  if (HAL_TIM_PWM_ConfigChannel(&htim9, &sConfigOC, TIM_CHANNEL_1) != HAL_OK)
  {
    Error_Handler();
  }
  if (HAL_TIM_PWM_ConfigChannel(&htim9, &sConfigOC, TIM_CHANNEL_2) != HAL_OK)
  {
    Error_Handler();
  }
  /* USER CODE BEGIN TIM9_Init 2 */
  HAL_TIM_MspPostInit(&htim9);
  /* USER CODE END TIM9_Init 2 */
  HAL_TIM_MspPostInit(&htim9);

}

static void MX_TIM10_Init(void)
{

  TIM_OC_InitTypeDef sConfigOC = {0};

  htim10.Instance = TIM10;
  htim10.Init.Prescaler = 10;
  htim10.Init.CounterMode = TIM_COUNTERMODE_UP;
  htim10.Init.Period = 999;
  htim10.Init.ClockDivision = TIM_CLOCKDIVISION_DIV1;
  htim10.Init.AutoReloadPreload = TIM_AUTORELOAD_PRELOAD_DISABLE;
  if (HAL_TIM_Base_Init(&htim10) != HAL_OK)
  {
    Error_Handler();
  }
  if (HAL_TIM_PWM_Init(&htim10) != HAL_OK)
  {
    Error_Handler();
  }
  sConfigOC.OCMode = TIM_OCMODE_PWM1;
  sConfigOC.Pulse = 0;
  sConfigOC.OCPolarity = TIM_OCPOLARITY_HIGH;
  sConfigOC.OCFastMode = TIM_OCFAST_DISABLE;
  if (HAL_TIM_PWM_ConfigChannel(&htim10, &sConfigOC, TIM_CHANNEL_1) != HAL_OK)
  {
    Error_Handler();
  }
  HAL_TIM_MspPostInit(&htim10);

}

static void MX_TIM11_Init(void)
{

  TIM_OC_InitTypeDef sConfigOC = {0};

  htim11.Instance = TIM11;
  htim11.Init.Prescaler = 10;
  htim11.Init.CounterMode = TIM_COUNTERMODE_UP;
  htim11.Init.Period = 999;
  htim11.Init.ClockDivision = TIM_CLOCKDIVISION_DIV1;
  htim11.Init.AutoReloadPreload = TIM_AUTORELOAD_PRELOAD_DISABLE;
  if (HAL_TIM_Base_Init(&htim11) != HAL_OK)
  {
    Error_Handler();
  }
  if (HAL_TIM_PWM_Init(&htim11) != HAL_OK)
  {
    Error_Handler();
  }
  sConfigOC.OCMode = TIM_OCMODE_PWM1;
  sConfigOC.Pulse = 0;
  sConfigOC.OCPolarity = TIM_OCPOLARITY_HIGH;
  sConfigOC.OCFastMode = TIM_OCFAST_DISABLE;
  if (HAL_TIM_PWM_ConfigChannel(&htim11, &sConfigOC, TIM_CHANNEL_1) != HAL_OK)
  {
    Error_Handler();
  }
  HAL_TIM_MspPostInit(&htim11);

}

static void MX_TIM13_Init(void)
{

  TIM_OC_InitTypeDef sConfigOC = {0};

  htim13.Instance = TIM13;
  htim13.Init.Prescaler = 5;
  htim13.Init.CounterMode = TIM_COUNTERMODE_UP;
  htim13.Init.Period = 999;
  htim13.Init.ClockDivision = TIM_CLOCKDIVISION_DIV1;
  htim13.Init.AutoReloadPreload = TIM_AUTORELOAD_PRELOAD_DISABLE;
  if (HAL_TIM_Base_Init(&htim13) != HAL_OK)
  {
    Error_Handler();
  }
  if (HAL_TIM_PWM_Init(&htim13) != HAL_OK)
  {
    Error_Handler();
  }
  sConfigOC.OCMode = TIM_OCMODE_PWM1;
  sConfigOC.Pulse = 0;
  sConfigOC.OCPolarity = TIM_OCPOLARITY_HIGH;
  sConfigOC.OCFastMode = TIM_OCFAST_DISABLE;
  if (HAL_TIM_PWM_ConfigChannel(&htim13, &sConfigOC, TIM_CHANNEL_1) != HAL_OK)
  {
    Error_Handler();
  }
  HAL_TIM_MspPostInit(&htim13);

}

static void MX_TIM14_Init(void)
{

  TIM_OC_InitTypeDef sConfigOC = {0};

  htim14.Instance = TIM14;
  htim14.Init.Prescaler = 5;
  htim14.Init.CounterMode = TIM_COUNTERMODE_UP;
  htim14.Init.Period = 999;
  htim14.Init.ClockDivision = TIM_CLOCKDIVISION_DIV1;
  htim14.Init.AutoReloadPreload = TIM_AUTORELOAD_PRELOAD_DISABLE;
  if (HAL_TIM_Base_Init(&htim14) != HAL_OK)
  {
    Error_Handler();
  }
  if (HAL_TIM_PWM_Init(&htim14) != HAL_OK)
  {
    Error_Handler();
  }
  sConfigOC.OCMode = TIM_OCMODE_PWM1;
  sConfigOC.Pulse = 0;
  sConfigOC.OCPolarity = TIM_OCPOLARITY_HIGH;
  sConfigOC.OCFastMode = TIM_OCFAST_DISABLE;
  if (HAL_TIM_PWM_ConfigChannel(&htim14, &sConfigOC, TIM_CHANNEL_1) != HAL_OK)
  {
    Error_Handler();
  }
  HAL_TIM_MspPostInit(&htim14);

}

static void MX_USART1_UART_Init(void)
{

  huart1.Instance = USART1;
  huart1.Init.BaudRate = 9600;
  huart1.Init.WordLength = UART_WORDLENGTH_8B;
  huart1.Init.StopBits = UART_STOPBITS_1;
  huart1.Init.Parity = UART_PARITY_NONE;
  huart1.Init.Mode = UART_MODE_TX_RX;
  huart1.Init.HwFlowCtl = UART_HWCONTROL_NONE;
  huart1.Init.OverSampling = UART_OVERSAMPLING_16;
  huart1.Init.OneBitSampling = UART_ONE_BIT_SAMPLE_DISABLE;
  huart1.AdvancedInit.AdvFeatureInit = UART_ADVFEATURE_NO_INIT;
  if (HAL_UART_Init(&huart1) != HAL_OK)
  {
    Error_Handler();
  }

}

static void MX_USART2_UART_Init(void)
{

  huart2.Instance = USART2;
  huart2.Init.BaudRate = 115200;
  huart2.Init.WordLength = UART_WORDLENGTH_8B;
  huart2.Init.StopBits = UART_STOPBITS_1;
  huart2.Init.Parity = UART_PARITY_NONE;
  huart2.Init.Mode = UART_MODE_TX_RX;
  huart2.Init.HwFlowCtl = UART_HWCONTROL_NONE;
  huart2.Init.OverSampling = UART_OVERSAMPLING_16;
  huart2.Init.OneBitSampling = UART_ONE_BIT_SAMPLE_DISABLE;
  huart2.AdvancedInit.AdvFeatureInit = UART_ADVFEATURE_NO_INIT;
  if (HAL_UART_Init(&huart2) != HAL_OK)
  {
    Error_Handler();
  }

}

static void MX_USART3_UART_Init(void)
{

  huart3.Instance = USART3;
  huart3.Init.BaudRate = 115200;
  huart3.Init.WordLength = UART_WORDLENGTH_8B;
  huart3.Init.StopBits = UART_STOPBITS_1;
  huart3.Init.Parity = UART_PARITY_NONE;
  huart3.Init.Mode = UART_MODE_TX_RX;
  huart3.Init.HwFlowCtl = UART_HWCONTROL_NONE;
  huart3.Init.OverSampling = UART_OVERSAMPLING_16;
  huart3.Init.OneBitSampling = UART_ONE_BIT_SAMPLE_DISABLE;
  huart3.AdvancedInit.AdvFeatureInit = UART_ADVFEATURE_NO_INIT;
  if (HAL_UART_Init(&huart3) != HAL_OK)
  {
    Error_Handler();
  }

}

static void MX_GPIO_Init(void)
{
  GPIO_InitTypeDef GPIO_InitStruct = {0};

  /* GPIO Ports Clock Enable */
  __HAL_RCC_GPIOE_CLK_ENABLE();
  __HAL_RCC_GPIOF_CLK_ENABLE();
  __HAL_RCC_GPIOH_CLK_ENABLE();
  __HAL_RCC_GPIOC_CLK_ENABLE();
  __HAL_RCC_GPIOA_CLK_ENABLE();
  __HAL_RCC_GPIOB_CLK_ENABLE();
  __HAL_RCC_GPIOD_CLK_ENABLE();
  __HAL_RCC_GPIOG_CLK_ENABLE();

  /*Configure GPIO pin Output Level */
  HAL_GPIO_WritePin(GPIOF, SLEW_DM_Pin|INV_DM_Pin|STM_GPIO3_Pin|STM_GPIO4_Pin
                          |EEPROM_WC_Pin, GPIO_PIN_RESET);

  /*Configure GPIO pin Output Level */
  HAL_GPIO_WritePin(GPIOB, STM_GPIO1_Pin|STM_GPIO2_Pin, GPIO_PIN_RESET);

  /*Configure GPIO pin Output Level */
  HAL_GPIO_WritePin(GPIOE, EN_DM_1_Pin|EN_DM_2_Pin|EN_DM_3_Pin|EN_DM_4_Pin, GPIO_PIN_RESET);

  /*Configure GPIO pin Output Level */
  HAL_GPIO_WritePin(GPIOG, OUT_LE3_Pin|OUT_LE4_Pin|OUT_LE5_Pin|OUT_LE6_Pin
                          |OUT_LE7_Pin|CAPT_O_RST_Pin, GPIO_PIN_RESET);

  /*Configure GPIO pin Output Level */
  HAL_GPIO_WritePin(GPIOA, ULTRA_DIR_Pin|WDI_Pin, GPIO_PIN_RESET);

  /*Configure GPIO pin : SF_DM_2_Pin */
  GPIO_InitStruct.Pin = SF_DM_2_Pin;
  GPIO_InitStruct.Mode = GPIO_MODE_INPUT;
  GPIO_InitStruct.Pull = GPIO_NOPULL;
  HAL_GPIO_Init(SF_DM_2_GPIO_Port, &GPIO_InitStruct);

  /*Configure GPIO pins : SLEW_DM_Pin INV_DM_Pin STM_GPIO3_Pin STM_GPIO4_Pin
                           EEPROM_WC_Pin */
  GPIO_InitStruct.Pin = SLEW_DM_Pin|INV_DM_Pin|STM_GPIO3_Pin|STM_GPIO4_Pin
                          |EEPROM_WC_Pin;
  GPIO_InitStruct.Mode = GPIO_MODE_OUTPUT_PP;
  GPIO_InitStruct.Pull = GPIO_NOPULL;
  GPIO_InitStruct.Speed = GPIO_SPEED_FREQ_LOW;
  HAL_GPIO_Init(GPIOF, &GPIO_InitStruct);

  /*Configure GPIO pins : STM_GPIO1_Pin STM_GPIO2_Pin */
  GPIO_InitStruct.Pin = STM_GPIO1_Pin|STM_GPIO2_Pin;
  GPIO_InitStruct.Mode = GPIO_MODE_OUTPUT_PP;
  GPIO_InitStruct.Pull = GPIO_NOPULL;
  GPIO_InitStruct.Speed = GPIO_SPEED_FREQ_LOW;
  HAL_GPIO_Init(GPIOB, &GPIO_InitStruct);

  /*Configure GPIO pins : EN_DM_1_Pin EN_DM_2_Pin EN_DM_3_Pin EN_DM_4_Pin */
  GPIO_InitStruct.Pin = EN_DM_1_Pin|EN_DM_2_Pin|EN_DM_3_Pin|EN_DM_4_Pin;
  GPIO_InitStruct.Mode = GPIO_MODE_OUTPUT_PP;
  GPIO_InitStruct.Pull = GPIO_NOPULL;
  GPIO_InitStruct.Speed = GPIO_SPEED_FREQ_LOW;
  HAL_GPIO_Init(GPIOE, &GPIO_InitStruct);

  /*Configure GPIO pin : SF_DM_3_Pin */
  GPIO_InitStruct.Pin = SF_DM_3_Pin;
  GPIO_InitStruct.Mode = GPIO_MODE_INPUT;
  GPIO_InitStruct.Pull = GPIO_NOPULL;
  HAL_GPIO_Init(SF_DM_3_GPIO_Port, &GPIO_InitStruct);

  /*Configure GPIO pins : OUT_LE3_Pin OUT_LE4_Pin OUT_LE5_Pin OUT_LE6_Pin
                           OUT_LE7_Pin CAPT_O_RST_Pin */
  GPIO_InitStruct.Pin = OUT_LE3_Pin|OUT_LE4_Pin|OUT_LE5_Pin|OUT_LE6_Pin
                          |OUT_LE7_Pin|CAPT_O_RST_Pin;
  GPIO_InitStruct.Mode = GPIO_MODE_OUTPUT_PP;
  GPIO_InitStruct.Pull = GPIO_NOPULL;
  GPIO_InitStruct.Speed = GPIO_SPEED_FREQ_LOW;
  HAL_GPIO_Init(GPIOG, &GPIO_InitStruct);

  /*Configure GPIO pins : ULTRA_DIR_Pin WDI_Pin */
  GPIO_InitStruct.Pin = ULTRA_DIR_Pin|WDI_Pin;
  GPIO_InitStruct.Mode = GPIO_MODE_OUTPUT_PP;
  GPIO_InitStruct.Pull = GPIO_NOPULL;
  GPIO_InitStruct.Speed = GPIO_SPEED_FREQ_LOW;
  HAL_GPIO_Init(GPIOA, &GPIO_InitStruct);

  /*Configure GPIO pin : SF_DM_4_Pin */
  GPIO_InitStruct.Pin = SF_DM_4_Pin;
  GPIO_InitStruct.Mode = GPIO_MODE_INPUT;
  GPIO_InitStruct.Pull = GPIO_NOPULL;
  HAL_GPIO_Init(SF_DM_4_GPIO_Port, &GPIO_InitStruct);

  /*Configure GPIO pins : MOTION_3_Pin MOTION_1_Pin */
  GPIO_InitStruct.Pin = MOTION_3_Pin|MOTION_1_Pin;
  GPIO_InitStruct.Mode = GPIO_MODE_INPUT;
  GPIO_InitStruct.Pull = GPIO_NOPULL;
  HAL_GPIO_Init(GPIOD, &GPIO_InitStruct);

  /*Configure GPIO pin : MOTION_6_Pin */
  GPIO_InitStruct.Pin = MOTION_6_Pin;
  GPIO_InitStruct.Mode = GPIO_MODE_INPUT;
  GPIO_InitStruct.Pull = GPIO_NOPULL;
  HAL_GPIO_Init(MOTION_6_GPIO_Port, &GPIO_InitStruct);

  /*Configure GPIO pin : SF_DM_1_Pin */
  GPIO_InitStruct.Pin = SF_DM_1_Pin;
  GPIO_InitStruct.Mode = GPIO_MODE_INPUT;
  GPIO_InitStruct.Pull = GPIO_NOPULL;
  HAL_GPIO_Init(SF_DM_1_GPIO_Port, &GPIO_InitStruct);

}

/* USER CODE BEGIN 4 */

void board_message_init(void) {
	HAL_UART_Transmit(&huart2, (uint8_t*)"\r\n", sizeof("\r\n"), HAL_MAX_DELAY);
	HAL_UART_Transmit(&huart2, (uint8_t*)"\r\n", sizeof("\r\n"), HAL_MAX_DELAY);
	HAL_UART_Transmit(&huart2, (uint8_t*)"\r\n", sizeof("\r\n"), HAL_MAX_DELAY);
	HAL_UART_Transmit(&huart2, (uint8_t*)"***********************************\r\n", sizeof("***********************************\r\n"), HAL_MAX_DELAY);
	HAL_UART_Transmit(&huart2, (uint8_t*)"* AsserVitesse_V01                *\r\n", sizeof("* AsserVitesse_V01                *\r\n"), HAL_MAX_DELAY);
	HAL_UART_Transmit(&huart2, (uint8_t*)"***********************************\r\n", sizeof("***********************************\r\n"), HAL_MAX_DELAY);
	HAL_UART_Transmit(&huart2, (uint8_t*)"\r\n", sizeof("\r\n"), HAL_MAX_DELAY);
}

void board_motors_init(void) {
	HAL_UART_Transmit(&huart2, (uint8_t*)"Initialisation des moteurs.....\r\n", sizeof("Initialisation des moteurs.....\r\n"), HAL_MAX_DELAY);

	HAL_GPIO_WritePin(EN_DM_1_GPIO_Port, EN_DM_1_Pin, GPIO_PIN_RESET);
	HAL_GPIO_WritePin(EN_DM_2_GPIO_Port, EN_DM_2_Pin, GPIO_PIN_RESET);
	HAL_GPIO_WritePin(EN_DM_3_GPIO_Port, EN_DM_3_Pin, GPIO_PIN_RESET);
	HAL_GPIO_WritePin(EN_DM_4_GPIO_Port, EN_DM_4_Pin, GPIO_PIN_RESET);

	/*HAL_GPIO_WritePin(EN_DM_1_GPIO_Port, EN_DM_1_Pin, GPIO_PIN_SET);
	HAL_GPIO_WritePin(EN_DM_2_GPIO_Port, EN_DM_2_Pin, GPIO_PIN_SET);
	HAL_GPIO_WritePin(EN_DM_3_GPIO_Port, EN_DM_3_Pin, GPIO_PIN_SET);
	HAL_GPIO_WritePin(EN_DM_4_GPIO_Port, EN_DM_4_Pin, GPIO_PIN_SET);*/

	HAL_GPIO_WritePin(SLEW_DM_GPIO_Port, SLEW_DM_Pin, GPIO_PIN_SET);
	HAL_GPIO_WritePin(INV_DM_GPIO_Port, INV_DM_Pin, GPIO_PIN_RESET);

	htim10.Instance->CCR1 = 0;	// MOTOR1 -> IN1
	htim11.Instance->CCR1 = 0;	// MOTOR1 -> IN2
	htim9.Instance->CCR1 = 0;	// MOTOR2 -> IN1
	htim9.Instance->CCR2 = 0;	// MOTOR2 -> IN2
	htim13.Instance->CCR1 = 0;	// MOTOR3 -> IN1
	htim14.Instance->CCR1 = 0;	// MOTOR3 -> IN2
	htim8.Instance->CCR3 = 0;	// MOTOR4 -> IN1
	htim8.Instance->CCR4 = 0;	// MOTOR4 -> IN2

	HAL_TIM_PWM_Start(&htim10, TIM_CHANNEL_1);
	HAL_TIM_PWM_Start(&htim11, TIM_CHANNEL_1);
	HAL_TIM_PWM_Start(&htim9, TIM_CHANNEL_1);
	HAL_TIM_PWM_Start(&htim9, TIM_CHANNEL_2);
	HAL_TIM_PWM_Start(&htim13, TIM_CHANNEL_1);
	HAL_TIM_PWM_Start(&htim14, TIM_CHANNEL_1);
	HAL_TIM_PWM_Start(&htim8, TIM_CHANNEL_3);
	HAL_TIM_PWM_Start(&htim8, TIM_CHANNEL_4);

}

void board_encodeurs_init(void) {
	HAL_UART_Transmit(&huart2, (uint8_t*)"Initialisation des encodeurs.....\r\n", sizeof("Initialisation des encodeurs.....\r\n"), HAL_MAX_DELAY);

	HAL_TIM_Encoder_Start(&htim4, TIM_CHANNEL_ALL);		// Encodeur M1
	HAL_TIM_Encoder_Start(&htim3, TIM_CHANNEL_ALL);		// Encodeur M2
	HAL_TIM_Encoder_Start(&htim2, TIM_CHANNEL_ALL);		// Encodeur M3
	HAL_TIM_Encoder_Start(&htim5, TIM_CHANNEL_ALL);		// Encodeur M4

}

/* USER CODE END 4 */

void Error_Handler(void)
{
}

/************************ (C) COPYRIGHT STMicroelectronics *****END OF FILE****/
